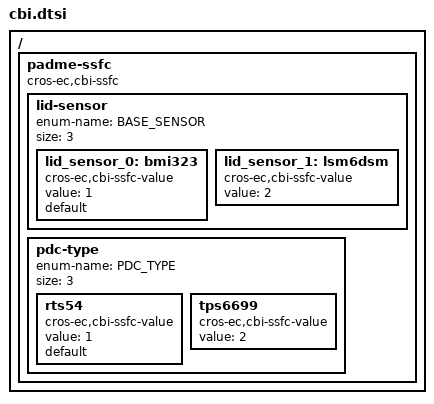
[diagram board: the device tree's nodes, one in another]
/* Copyright 2025 The ChromiumOS Authors
 * Use of this source code is governed by a BSD-style license that can be
 * found in the LICENSE file.
 */

/ {
	padme-ssfc {
		compatible = "cros-ec,cbi-ssfc";

		/* SSFC field to identify BASE motion sensor. */
		lid-sensor {
			enum-name = "BASE_SENSOR";
			size = <3>;

			lid_sensor_0: bmi323 {
				compatible = "cros-ec,cbi-ssfc-value";
				status = "okay";
				value = <1>;
				default;
			};
			lid_sensor_1: lsm6dsm {
				compatible = "cros-ec,cbi-ssfc-value";
				status = "okay";
				value = <2>;
			};
		};
		/* SSFC field to identify PDC type.*/
		pdc-type {
			enum-name = "PDC_TYPE";
			size = <3>;

			rts54: rts54 {
				compatible = "cros-ec,cbi-ssfc-value";
				status = "okay";
				value = <1>;
				default;
			};
			tps6699: tps6699 {
				compatible = "cros-ec,cbi-ssfc-value";
				status = "okay";
				value = <2>;
			};
		};
	};
};
